# ATxmega192D3 device description
Architecture: AVR8_XMEGA; Family: AVR XMEGA
Registers are 8-bit, access not given, no defined reset value unless marked. A register's access mark holds for its fields unless they carry their own. Offsets are from the block's base; [hi:lo] are bit positions; {n}, {i} and the like mark numbered series; 'fields as' and 'values as' point back to an identical list.

## PORTCFG — I/O port Configuration
Instances: PORTCFG 0x00B0
0x00 MPCMASK — Multi-pin Configuration Mask
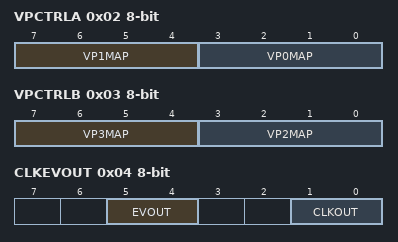
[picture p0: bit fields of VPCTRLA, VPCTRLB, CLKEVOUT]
0x02 VPCTRLA — Virtual Port Control Register A
  [7:4] VP1MAP — Virtual Port 1 Mapping
    0=PORTA (Mapped To PORTA); 1=PORTB (Mapped To PORTB); 2=PORTC (Mapped To PORTC); 3=PORTD (Mapped To PORTD); 4=PORTE (Mapped To PORTE); 5=PORTF (Mapped To PORTF); 6=PORTG (Mapped To PORTG); 7=PORTH (Mapped To PORTH); 8=PORTJ (Mapped To PORTJ); 9=PORTK (Mapped To PORTK); 10=PORTL (Mapped To PORTL); 11=PORTM (Mapped To PORTM); 12=PORTN (Mapped To PORTN); 13=PORTP (Mapped To PORTP); 14=PORTQ (Mapped To PORTQ); 15=PORTR (Mapped To PORTR)
  [3:0] VP0MAP — Virtual Port 0 Mapping
    values as VP1MAP
0x03 VPCTRLB — Virtual Port Control Register B
  [7:4] VP3MAP — Virtual Port 3 Mapping
    values as VPCTRLA.VP1MAP
  [3:0] VP2MAP — Virtual Port 2 Mapping
    values as VPCTRLA.VP1MAP
0x04 CLKEVOUT — Clock and Event Out Register
  [5:4] EVOUT — Event Output Port
    0=OFF (Event Output Disabled); 1=PC7 (Event Channel 7 Output on Port C pin 7); 2=PD7 (Event Channel 7 Output on Port D pin 7); 3=PE7 (Event Channel 7 Output on Port E pin 7)
  [1:0] CLKOUT — Clock Output Port
    0=OFF (Clock Output Disabled); 1=PC7 (Clock Output on Port C pin 7); 2=PD7 (Clock Output on Port D pin 7); 3=PE7 (Clock Output on Port E pin 7)

## VPORT — Virtual Port
Instances: VPORT{n} {0x10+4n} (n=0..3)
0x00 DIR — I/O Port Data Direction
0x01 OUT — I/O Port Output
0x02 IN — I/O Port Input
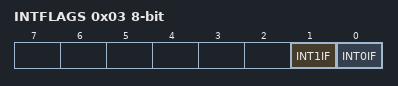
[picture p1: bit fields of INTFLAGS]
0x03 INTFLAGS — Interrupt Flag Register
  [1] INT1IF — Port Interrupt 1 Flag
  [0] INT0IF — Port Interrupt 0 Flag

## PORT — I/O Ports
Instances: PORTA 0x0600, PORTB 0x0620, PORTC 0x0640, PORTD 0x0660, PORTE 0x0680, PORTF 0x06A0, PORTR 0x07E0
0x00 DIR — I/O Port Data Direction
0x01 DIRSET — I/O Port Data Direction Set
0x02 DIRCLR — I/O Port Data Direction Clear
0x03 DIRTGL — I/O Port Data Direction Toggle
0x04 OUT — I/O Port Output
0x05 OUTSET — I/O Port Output Set
0x06 OUTCLR — I/O Port Output Clear
0x07 OUTTGL — I/O Port Output Toggle
0x08 IN — I/O port Input
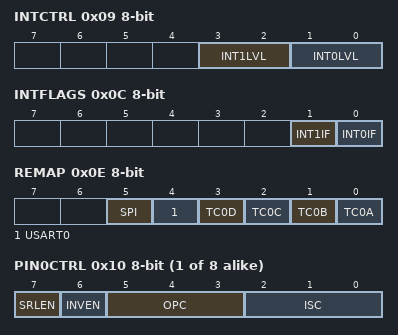
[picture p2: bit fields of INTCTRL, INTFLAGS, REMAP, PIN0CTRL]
0x09 INTCTRL — Interrupt Control Register
  [3:2] INT1LVL — Port Interrupt 1 Level
    0=OFF (Interrupt Disabled); 1=LO (Low Level); 2=MED (Medium Level); 3=HI (High Level)
  [1:0] INT0LVL — Port Interrupt 0 Level
    values as INT1LVL
0x0A INT0MASK — Port Interrupt 0 Mask
0x0B INT1MASK — Port Interrupt 1 Mask
0x0C INTFLAGS — Interrupt Flag Register
  [1] INT1IF — Port Interrupt 1 Flag
  [0] INT0IF — Port Interrupt 0 Flag
0x0E REMAP — Pin Remap Register (available for PORTC to PORTF only)
  [5] SPI — SPI Remap
  [4] USART0 — USART0 Remap
  [3] TC0D — Timer/Counter 0 Output Compare D
  [2] TC0C — Timer/Counter 0 Output Compare C
  [1] TC0B — Timer/Counter 0 Output Compare B
  [0] TC0A — Timer/Counter 0 Output Compare A
{0x10+i} PIN{i}CTRL (i=0..7) — Pin {i} Control Register
  [7] SRLEN — Slew Rate Enable
  [6] INVEN — Inverted I/O Enable
  [5:3] OPC — Output/Pull Configuration
    0=TOTEM (Totempole); 1=BUSKEEPER (Totempole w/ Bus keeper on Input and Output); 2=PULLDOWN (Totempole w/ Pull-down on Input); 3=PULLUP (Totempole w/ Pull-up on Input); 4=WIREDOR; 5=WIREDAND; 6=WIREDORPULL (Wired OR w/ Pull-down); 7=WIREDANDPULL (Wired AND w/ Pull-up)
  [2:0] ISC — Input/Sense Configuration
    0=BOTHEDGES (Sense Both Edges); 1=RISING (Sense Rising Edge); 2=FALLING (Sense Falling Edge); 3=LEVEL (Sense Level (Transparent For Events)); 7=INPUT_DISABLE (Disable Digital Input Buffer)

## AWEX (TC module) — Advanced Waveform Extension
Instances: AWEXC 0x880, AWEXE 0xA80
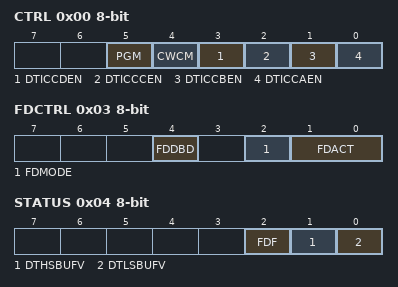
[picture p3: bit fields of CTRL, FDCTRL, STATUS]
0x00 CTRL — Control Register
  [5] PGM — Pattern Generation Mode
  [4] CWCM — Common Waveform Channel Mode
  [3] DTICCDEN — Dead Time Insertion Compare Channel D Enable
  [2] DTICCCEN — Dead Time Insertion Compare Channel C Enable
  [1] DTICCBEN — Dead Time Insertion Compare Channel B Enable
  [0] DTICCAEN — Dead Time Insertion Compare Channel A Enable
0x02 FDEMASK — Fault Detection Event Mask
0x03 FDCTRL — Fault Detection Control Register
  [4] FDDBD — Fault Detect on Disable Break Disable
  [2] FDMODE — Fault Detect Mode
  [1:0] FDACT — Fault Detect Action
    0=NONE (No Fault Protection); 1=CLEAROE (Clear Output Enable Bits); 3=CLEARDIR (Clear I/O Port Direction Bits)
0x04 STATUS
  [2] FDF — Fault Detect Flag
  [1] DTHSBUFV — Dead Time High Side Buffer Valid
  [0] DTLSBUFV — Dead Time Low Side Buffer Valid
0x06 DTBOTH — Dead Time Both Sides
0x07 DTBOTHBUF — Dead Time Both Sides Buffer
0x08 DTLS — Dead Time Low Side
0x09 DTHS — Dead Time High Side
0x0A DTLSBUF — Dead Time Low Side Buffer
0x0B DTHSBUF — Dead Time High Side Buffer
0x0C OUTOVEN — Output Override Enable
